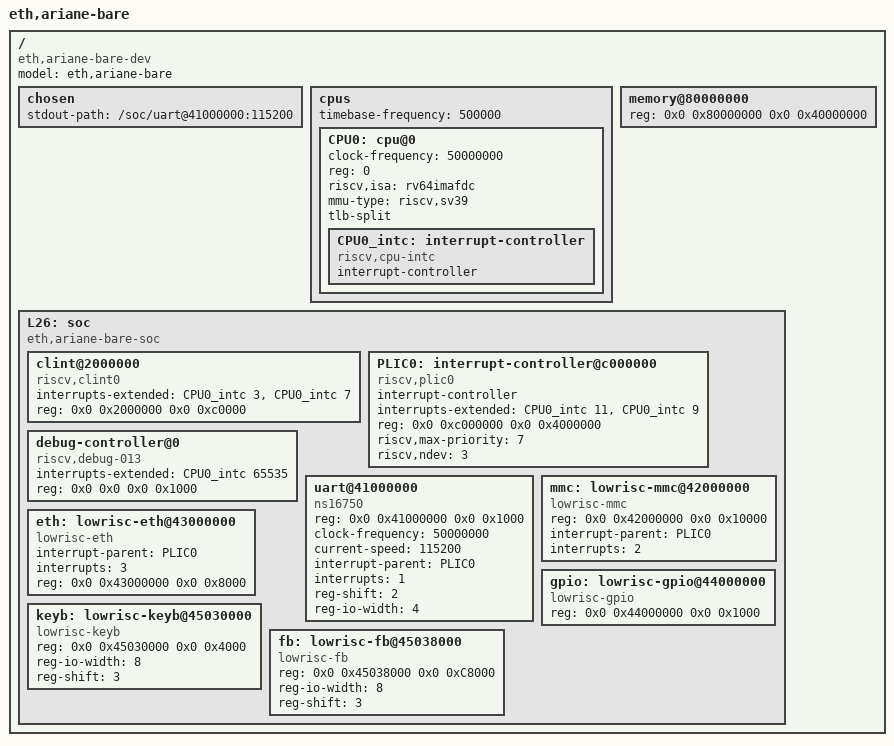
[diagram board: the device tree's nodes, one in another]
/dts-v1/;

/ {
  #address-cells = <2>;
  #size-cells = <2>;
  compatible = "eth,ariane-bare-dev";
  model = "eth,ariane-bare";
  chosen {
    stdout-path = "/soc/uart@41000000:115200";
  };
  cpus {
    #address-cells = <1>;
    #size-cells = <0>;
    timebase-frequency = <500000>; // 0.5 MHz
    CPU0: cpu@0 {
      clock-frequency = <50000000>; // 50 MHz
      device_type = "cpu";
      reg = <0>;
      status = "okay";
      compatible = "", "riscv";
      riscv,isa = "rv64imafdc";
      mmu-type = "riscv,sv39";
      tlb-split;
      // HLIC - hart local interrupt controller
      CPU0_intc: interrupt-controller {
        #interrupt-cells = <1>;
        interrupt-controller;
        compatible = "riscv,cpu-intc";
      };
    };
  };
  memory@80000000 {
    device_type = "memory";
    reg = <0x0 0x80000000 0x0 0x40000000>;
  };
  L26: soc {
    #address-cells = <2>;
    #size-cells = <2>;
    compatible = "eth,ariane-bare-soc", "simple-bus";
    ranges;
    clint@2000000 {
      compatible = "riscv,clint0";
      interrupts-extended = <&CPU0_intc 3 &CPU0_intc 7>;
      reg = <0x0 0x2000000 0x0 0xc0000>;
      reg-names = "control";
    };
    PLIC0: interrupt-controller@c000000 {
      #address-cells = <0>;
      #interrupt-cells = <1>;
      compatible = "riscv,plic0";
      interrupt-controller;
      interrupts-extended = <&CPU0_intc 11 &CPU0_intc 9>;
      reg = <0x0 0xc000000 0x0 0x4000000>;
      riscv,max-priority = <7>;
      riscv,ndev = <3>;
    };
    debug-controller@0 {
      compatible = "riscv,debug-013";
      interrupts-extended = <&CPU0_intc 65535>;
      reg = <0x0 0x0 0x0 0x1000>;
      reg-names = "control";
    };
    uart@41000000 {
      compatible = "ns16750";
      reg = <0x0 0x41000000 0x0 0x1000>;
      clock-frequency = <50000000>;
      current-speed = <115200>;
      interrupt-parent = <&PLIC0>;
      interrupts = <1>;
      reg-shift = <2>; // regs are spaced on 32 bit boundary
      reg-io-width = <4>; // only 32-bit access are supported
    };
    mmc: lowrisc-mmc@42000000 {
      reg = <0x0 0x42000000 0x0 0x10000>;
      interrupt-parent = <&PLIC0>;
      interrupts = <2>;
      compatible = "lowrisc-mmc";
      };

    eth: lowrisc-eth@43000000 {
      compatible = "lowrisc-eth";
      device_type = "network";
      interrupt-parent = <&PLIC0>;
      interrupts = <3>;
      reg = <0x0 0x43000000 0x0 0x8000>;
    };
    gpio: lowrisc-gpio@44000000 {
      compatible = "lowrisc-gpio";
      reg = <0x0 0x44000000 0x0 0x1000 >;
    };
    keyb: lowrisc-keyb@45030000 {
            reg = <0x0 0x45030000 0x0 0x4000>;
            reg-io-width = <8>;
            reg-shift = <3>;
            compatible = "lowrisc-keyb";
    };
    fb: lowrisc-fb@45038000 {
            reg = <0x0 0x45038000 0x0 0xC8000>;
            reg-io-width = <8>;
            reg-shift = <3>;
            compatible = "lowrisc-fb";
    };
  };
};
